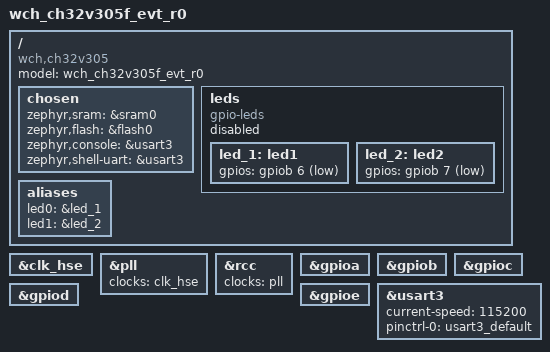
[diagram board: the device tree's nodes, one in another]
/*
 * Copyright (c) 2026 James Bennion-Pedley
 * SPDX-License-Identifier: Apache-2.0
 */

#include <wch/ch32v305/ch32v305fb.dtsi>
#include <zephyr/dt-bindings/gpio/gpio.h>
#include <zephyr/dt-bindings/input/input-event-codes.h>
#include "ch32v305f_evt_r0-pinctrl.dtsi"

/ {
	model = "wch_ch32v305f_evt_r0";
	compatible = "wch,ch32v305";

	chosen {
		zephyr,sram = &sram0;
		zephyr,flash = &flash0;
		zephyr,console = &usart3;
		zephyr,shell-uart = &usart3;
	};

	leds {
		compatible = "gpio-leds";

		/*
		 * To get LEDs on CH32V305F-EVT working, you have to use jumper wires to
		 * connect them to PB6/PB7 I/0 pins. And change status to "okay".
		 */
		status = "disabled";

		led_1: led1 {
			gpios = <&gpiob 6 GPIO_ACTIVE_LOW>;
		};

		led_2: led2 {
			gpios = <&gpiob 7 GPIO_ACTIVE_LOW>;
		};
	};

	aliases {
		led0 = &led_1;
		led1 = &led_2;
	};
};

&clk_hse {
	status = "okay";
};

&pll {
	clocks = <&clk_hse>;
	status = "okay";
};

&rcc {
	clocks = <&pll>;
};

&gpioa {
	status = "okay";
};

&gpiob {
	status = "okay";
};

&gpioc {
	status = "okay";
};

&gpiod {
	status = "okay";
};

&gpioe {
	status = "okay";
};

&usart3 {
	status = "okay";
	current-speed = <115200>;
	pinctrl-0 = <&usart3_default>;
	pinctrl-names = "default";
};
